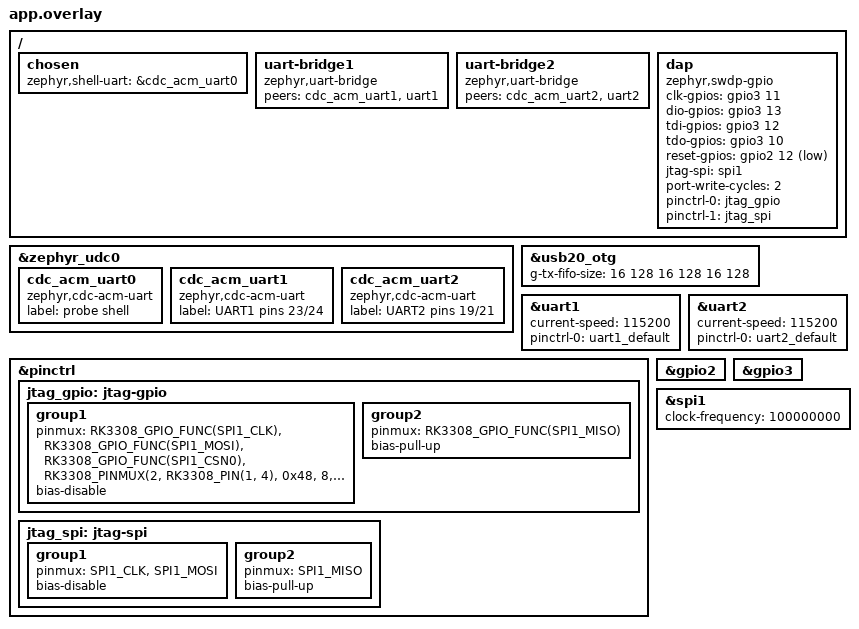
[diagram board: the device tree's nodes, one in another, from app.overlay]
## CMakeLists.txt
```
# SPDX-FileCopyrightText: Copyright The Zephyr Project Contributors
# SPDX-License-Identifier: Apache-2.0

cmake_minimum_required(VERSION 3.20.0)
find_package(Zephyr REQUIRED HINTS $ENV{ZEPHYR_BASE})
project(rk3308_usb_probe)

include(${ZEPHYR_BASE}/samples/subsys/usb/common/common.cmake)
target_sources(app PRIVATE src/main.c src/cpufreq.c)

target_sources_ifdef(CONFIG_DAP_BACKEND_TCP app PRIVATE src/dap.c)

if(CONFIG_SSH_SERVER)
  target_sources(app PRIVATE src/ssh.c)
  if(NOT CONFIG_USB_PROBE_SSH_HOST_KEY STREQUAL "")
    get_filename_component(host_key ${CONFIG_USB_PROBE_SSH_HOST_KEY}
                           ABSOLUTE BASE_DIR ${APPLICATION_SOURCE_DIR})
    set(gen_dir ${ZEPHYR_BINARY_DIR}/include/generated)
    generate_inc_file_for_target(app ${host_key} ${gen_dir}/ssh_host_key.der.inc)
    target_compile_definitions(app PRIVATE USB_PROBE_SSH_HOST_KEY_INC)
  endif()
endif()
```

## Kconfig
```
# Copyright The Zephyr Project Contributors
# SPDX-License-Identifier: Apache-2.0

# USB sample options (VID/PID, strings) of the in-tree USB samples
source "samples/subsys/usb/common/Kconfig.sample_usbd"

if SSH_SERVER

config USB_PROBE_SSH_USERNAME
	string "SSH user name (empty: any)"
	default "root"

config USB_PROBE_SSH_PASSWORD
	string "SSH password"
	default ""
	help
	  Stored in clear text in the image. Empty: the server is not
	  started.

config USB_PROBE_SSH_HOST_KEY
	string "RSA host key file (DER)"
	default ""
	help
	  Private RSA key built into the image, relative to the application
	  directory or absolute, e.g. made with
	  "openssl genpkey -algorithm RSA -pkeyopt rsa_keygen_bits:2048
	  -outform DER -out host_key.der". The probe has no storage, so
	  without it a new key (and fingerprint) is generated on every
	  boot.

config USB_PROBE_SSH_HOST_KEY_BITS
	int "Size of a host key generated at boot"
	default 2048

endif

source "Kconfig.zephyr"
```

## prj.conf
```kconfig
CONFIG_USB_DEVICE_STACK_NEXT=y
CONFIG_SAMPLE_USBD_PID=0x0001
CONFIG_SAMPLE_USBD_PRODUCT="RK3308 lab probe"
CONFIG_SAMPLE_USBD_MAX_POWER=250

CONFIG_SERIAL=y
CONFIG_UART_INTERRUPT_DRIVEN=y
CONFIG_UART_LINE_CTRL=y
CONFIG_UART_USE_RUNTIME_CONFIGURE=y
CONFIG_CDC_ACM_SERIAL_INITIALIZE_AT_BOOT=n
CONFIG_UART_BRIDGE_BUF_SIZE=4096

# probe shell on the first CDC ACM port, log on the console UART
CONFIG_SHELL=y
CONFIG_SHELL_BACKEND_SERIAL=y
CONFIG_SHELL_BACKEND_SERIAL_CHECK_DTR=y
CONFIG_SHELL_LOG_BACKEND=n
CONFIG_KERNEL_SHELL=y
CONFIG_DEVMEM_SHELL=y
# log off for now: with it on, nothing reaches UART0 on this board
CONFIG_LOG=n

# "kernel reboot": PSCI SYSTEM_RESET
CONFIG_REBOOT=y

# micro SD: FAT partition mounted at /SD:, the boot area (MBR, idbloader at
# sector 64, FIT at sector 16384) written by "fwupdate ymodem"
CONFIG_SDHC=y
CONFIG_DISK_ACCESS=y
CONFIG_SDMMC_STACK=y
CONFIG_DISK_DRIVER_SDMMC=y
CONFIG_FILE_SYSTEM=y
CONFIG_FILE_SYSTEM_SHELL=y
CONFIG_FAT_FILESYSTEM_ELM=y
CONFIG_FS_FATFS_LFN=y
# mkfs over the whole card would cover the boot area
CONFIG_FS_FATFS_MOUNT_MKFS=n
CONFIG_FWUPDATE=y
CONFIG_FWUPDATE_BOOT_DISK=y
CONFIG_FWUPDATE_BOOT_DISK_NAME="SD"
# up to the end of a FIT of at most 1 MiB at sector 16384
CONFIG_FWUPDATE_BOOT_DISK_SIZE=0x900000
CONFIG_MAIN_STACK_SIZE=4096

# "cpu freq": core clock with vdd_core (PWM regulator)
CONFIG_PWM=y
CONFIG_REGULATOR=y
```

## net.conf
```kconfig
# Ethernet (RMII + RTL8201F): DHCP, mDNS (rk3308-probe-<mac>.local), the
# shell over SSH. EXTRA_CONF_FILE=net.conf and
# -DCONFIG_USB_PROBE_SSH_PASSWORD=\"...\"; ssh root@rk3308-probe-<mac>.local
CONFIG_NETWORKING=y
CONFIG_NET_L2_ETHERNET=y
CONFIG_NET_IPV4=y
CONFIG_NET_IPV6=n
CONFIG_NET_TCP=y
CONFIG_NET_UDP=y
CONFIG_NET_DHCPV4=y
# first DISCOVER 1..2 s after the link, not up to 10 s (RFC 2131 4.4.1)
CONFIG_NET_DHCPV4_INITIAL_DELAY_MAX=2
CONFIG_NET_SOCKETS=y
CONFIG_NET_HOSTNAME_ENABLE=y
CONFIG_NET_HOSTNAME="rk3308-probe"
CONFIG_NET_HOSTNAME_UNIQUE=y
CONFIG_MDNS_RESPONDER=y
CONFIG_NET_SHELL=y
CONFIG_NET_PKT_RX_COUNT=32
CONFIG_NET_PKT_TX_COUNT=32
CONFIG_NET_BUF_RX_COUNT=64
CONFIG_NET_BUF_TX_COUNT=64
CONFIG_NET_RX_STACK_SIZE=4096
# no TRNG driver for the RK3308 yet: not a source of real entropy
CONFIG_TEST_RANDOM_GENERATOR=y
CONFIG_HWINFO_SHELL=y

CONFIG_SSH_SERVER=y
CONFIG_SSH_SERVER_MAX_CLIENTS=2
CONFIG_SSH_MAX_CHANNELS=2
CONFIG_SSH_MAX_HOST_KEYS=1
# the channel receive window: with the default 256 bytes, one round trip per
# 128 bytes caps an upload at about 20 kB/s
CONFIG_SSH_CHANNEL_BUF_SIZE=16384
CONFIG_MBEDTLS=y
# RSA key generation in main()
CONFIG_MAIN_STACK_SIZE=16384
# "fwupdate tcp" (nc -N <probe> 6969 < <img>-boot.bin) and
# "scp -O <img>-boot.bin root@<probe>:/fw"
CONFIG_FWUPDATE_TCP=y
CONFIG_SHELL_SSH_SCP=y
# ssh <probe> '<command>'
CONFIG_SHELL_SSH_EXEC=y
CONFIG_SHELL_DUMMY_INIT_LOG_LEVEL_NONE=y
CONFIG_SHELL_PROMPT_DUMMY=""
CONFIG_ZVFS_POLL_MAX=10
CONFIG_ZVFS_OPEN_MAX=16

# CMSIS-DAP over TCP (port 4441): SWD/JTAG on header 2, JTAG bytes by SPI1
CONFIG_GPIO=y
CONFIG_SPI=y
CONFIG_DAP=y
CONFIG_DAP_BACKEND_TCP=y
CONFIG_CMSIS_DAP_PROBE_NAME="RK3308 lab probe"
```

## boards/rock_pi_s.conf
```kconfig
# Buffer DMA (the FIFO mode does not complete control OUT data stages here).
# Hibernation off: power-down mode not verified on the RK3308.
CONFIG_UDC_DWC2_DMA=y
CONFIG_UDC_DWC2_HIBERNATION=n
# 512 bytes of driver thread stack are 96 % used on aarch64
CONFIG_UDC_DWC2_STACK_SIZE=1024
```

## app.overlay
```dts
/*
 * Copyright The Zephyr Project Contributors
 * SPDX-License-Identifier: Apache-2.0
 *
 * ACM0: probe shell. ACM1: UART1 (header pins 24 TX, 23 RX). ACM2: UART2
 * M0 (pins 19 TX, 21 RX). The host sets the line coding of each bridged
 * port. UART0 (pins 8/10) stays the console of the probe.
 */

/ {
	chosen {
		zephyr,shell-uart = &cdc_acm_uart0;
	};

	uart-bridge1 {
		compatible = "zephyr,uart-bridge";
		peers = <&cdc_acm_uart1 &uart1>;
	};

	uart-bridge2 {
		compatible = "zephyr,uart-bridge";
		peers = <&cdc_acm_uart2 &uart2>;
	};
};

&zephyr_udc0 {
	cdc_acm_uart0: cdc_acm_uart0 {
		compatible = "zephyr,cdc-acm-uart";
		label = "probe shell";
	};

	cdc_acm_uart1: cdc_acm_uart1 {
		compatible = "zephyr,cdc-acm-uart";
		label = "UART1 pins 23/24";
	};

	cdc_acm_uart2: cdc_acm_uart2 {
		compatible = "zephyr,cdc-acm-uart";
		label = "UART2 pins 19/21";
	};
};

/*
 * TX FIFO per IN endpoint, in the order the CDC ACM functions take them
 * (lowest free number first): notification (interrupt), data (bulk) for
 * each port. Bulk IN at high speed needs 128 words (512 bytes).
 */
&usb20_otg {
	g-tx-fifo-size = <16 128 16 128 16 128>;
};

&uart1 {
	status = "okay";
	current-speed = <115200>;
	pinctrl-0 = <&uart1_default>;
	pinctrl-names = "default";
};

&uart2 {
	status = "okay";
	current-speed = <115200>;
	pinctrl-0 = <&uart2_default>;
	pinctrl-names = "default";
};

/*
 * JTAG/SWD on header 2: 41 TCK/SWCLK (GPIO3_B3, SPI1_CLK), 39 TMS/SWDIO
 * (GPIO3_B5), 40 TDI (GPIO3_B4, SPI1_MOSI), 42 TDO (GPIO3_B2, SPI1_MISO),
 * 43 nRESET (GPIO2_B4). GPIO functions by default; SPI1 shifts the whole
 * bytes of JTAG sequences with its pads switched to SPI ("spi" state).
 * Served as CMSIS-DAP over TCP (net.conf).
 */
&pinctrl {
	jtag_gpio: jtag-gpio {
		group1 {
			pinmux = <RK3308_GPIO_FUNC(SPI1_CLK)>, <RK3308_GPIO_FUNC(SPI1_MOSI)>,
				 <RK3308_GPIO_FUNC(SPI1_CSN0)>,
				 <RK3308_PINMUX(2, RK3308_PIN(1, 4), 0x48, 8, 2, 0)>;
			bias-disable;
		};

		group2 {
			pinmux = <RK3308_GPIO_FUNC(SPI1_MISO)>;
			bias-pull-up;
		};
	};

	jtag_spi: jtag-spi {
		group1 {
			pinmux = <SPI1_CLK>, <SPI1_MOSI>;
			bias-disable;
		};

		group2 {
			pinmux = <SPI1_MISO>;
			bias-pull-up;
		};
	};
};

&gpio2 {
	status = "okay";
};

&gpio3 {
	status = "okay";
};

/* SCK up to 50 MHz (spiclk / 2) */
&spi1 {
	clock-frequency = <100000000>;
	status = "okay";
};

/ {
	dap: dap {
		compatible = "zephyr,swdp-gpio";
		clk-gpios = <&gpio3 11 GPIO_ACTIVE_HIGH>;
		dio-gpios = <&gpio3 13 GPIO_ACTIVE_HIGH>;
		tdi-gpios = <&gpio3 12 GPIO_ACTIVE_HIGH>;
		tdo-gpios = <&gpio3 10 GPIO_ACTIVE_HIGH>;
		reset-gpios = <&gpio2 12 GPIO_ACTIVE_LOW>;
		jtag-spi = <&spi1>;
		port-write-cycles = <2>;
		pinctrl-0 = <&jtag_gpio>;
		pinctrl-1 = <&jtag_spi>;
		pinctrl-names = "default", "spi";
	};
};
```

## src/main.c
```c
/*
 * Copyright The Zephyr Project Contributors
 * SPDX-License-Identifier: Apache-2.0
 *
 * RK3308 as a lab probe: USB composite device with CDC ACM ports, the first
 * one the probe's shell, the others bridged to UARTs (zephyr,uart-bridge);
 * the line coding the host sets on a bridged port is applied to its UART.
 * The FAT partition of a micro SD card is mounted at /SD:; "fwupdate"
 * writes the card's boot area. With net.conf: Ethernet with DHCP, mDNS
 * (rk3308-probe-<mac>.local), the shell over SSH and CMSIS-DAP over TCP
 * (SWD/JTAG on header 2).
 */

#include <ff.h>
#include <sample_usbd.h>

#include <zephyr/device.h>
#include <zephyr/drivers/uart/uart_bridge.h>
#include <zephyr/fs/fs.h>
#include <zephyr/kernel.h>
#include <zephyr/logging/log.h>
#include <zephyr/net/net_if.h>
#include <zephyr/net/dhcpv4.h>
#include <zephyr/sys/printk.h>
#include <zephyr/usb/usbd.h>

#include "probe.h"

LOG_MODULE_REGISTER(usb_probe, LOG_LEVEL_INF);

static const struct device *const bridges[] = {
	DT_FOREACH_STATUS_OKAY(zephyr_uart_bridge, DEVICE_DT_GET_COMMA)
};

static FATFS sd_fat;
static struct fs_mount_t sd_mnt = {
	.type = FS_FATFS,
	.fs_data = &sd_fat,
	.mnt_point = "/SD:",
};

static void msg_cb(struct usbd_context *const ctx, const struct usbd_msg *msg)
{
	if (msg->type == USBD_MSG_CDC_ACM_LINE_CODING ||
	    msg->type == USBD_MSG_CDC_ACM_CONTROL_LINE_STATE) {
		/* bridges not holding msg->dev skip it */
		for (size_t i = 0; i < ARRAY_SIZE(bridges); i++) {
			uart_bridge_settings_update(msg->dev, bridges[i]);
		}
		return;
	}
	LOG_INF("USB: %s", usbd_msg_type_string(msg->type));

	if (usbd_can_detect_vbus(ctx)) {
		if (msg->type == USBD_MSG_VBUS_READY && usbd_enable(ctx) != 0) {
			LOG_ERR("USB enable failed");
		}
		if (msg->type == USBD_MSG_VBUS_REMOVED && usbd_disable(ctx) != 0) {
			LOG_ERR("USB disable failed");
		}
	}
}

int main(void)
{
	int ret;
	struct usbd_context *usbd = sample_usbd_init_device(msg_cb);

	if (usbd == NULL) {
		LOG_ERR("USB device init failed");
		return -ENODEV;
	}
	if (!usbd_can_detect_vbus(usbd) && usbd_enable(usbd) != 0) {
		LOG_ERR("USB enable failed");
		return -EIO;
	}
	LOG_INF("USB probe: %zu UART bridges", ARRAY_SIZE(bridges));

	ret = fs_mount(&sd_mnt);
	printk("SD: %s (%d)\n", ret == 0 ? "mounted at /SD:" : "no card or no FAT", ret);

	if (IS_ENABLED(CONFIG_NET_DHCPV4) && net_if_get_default() != NULL) {
		struct net_linkaddr *ll = net_if_get_link_addr(net_if_get_default());

		printk("net: MAC %02x:%02x:%02x:%02x:%02x:%02x, DHCP\n", ll->addr[0],
		       ll->addr[1], ll->addr[2], ll->addr[3], ll->addr[4], ll->addr[5]);
		net_dhcpv4_start(net_if_get_default());
	}
	if (IS_ENABLED(CONFIG_SSH_SERVER)) {
		probe_ssh_start();
	}
	if (IS_ENABLED(CONFIG_DAP_BACKEND_TCP)) {
		probe_dap_start();
	}
	return 0;
}
```

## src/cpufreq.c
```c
/*
 * Copyright The Zephyr Project Contributors
 * SPDX-License-Identifier: Apache-2.0
 *
 * "cpu freq [MHz]": core clock at one of the operating points of the Linux
 * RK3308 devicetree, vdd_core (PWM regulator) set to the voltage of the
 * point first when the clock goes up and after it when it goes down.
 * "cpu vdd <mV>" sets vdd_core alone (to check it with a meter).
 * Until either is used, vdd_core runs at the voltage strapped on the board.
 */

#include <stdlib.h>

#include <zephyr/device.h>
#include <zephyr/drivers/clock_control.h>
#include <zephyr/drivers/regulator.h>
#include <zephyr/dt-bindings/clock/rk3308-cru.h>
#include <zephyr/shell/shell.h>

struct opp {
	uint16_t mhz;
	uint16_t mv;
};

static const struct opp opps[] = {
	{408, 950},
	{600, 950},
	{816, 1025},
	{1008, 1125},
};

static const struct device *const cru = DEVICE_DT_GET(DT_NODELABEL(cru_clk));
static const struct device *const vdd = DEVICE_DT_GET(DT_NODELABEL(vdd_core));

static void show(const struct shell *sh)
{
	uint32_t hz = 0;
	int32_t uv;

	(void)clock_control_get_rate(cru, (clock_control_subsys_t)ARMCLK, &hz);
	if (regulator_get_voltage(vdd, &uv) == 0) {
		shell_print(sh, "cores %u MHz, vdd_core %d mV", hz / 1000000U, uv / 1000);
	} else {
		shell_print(sh, "cores %u MHz, vdd_core as strapped (not set)", hz / 1000000U);
	}
}

static int set_mv(const struct shell *sh, uint32_t mv)
{
	int ret = regulator_set_voltage(vdd, mv * 1000, mv * 1000);

	if (ret != 0) {
		shell_error(sh, "vdd_core %u mV: %d", mv, ret);
	}
	return ret;
}

static int cmd_freq(const struct shell *sh, size_t argc, char **argv)
{
	const struct opp *o = NULL;
	uint32_t old = 0, mhz;
	int ret;

	if (argc < 2) {
		show(sh);
		return 0;
	}
	mhz = strtoul(argv[1], NULL, 0);
	for (size_t i = 0; i < ARRAY_SIZE(opps); i++) {
		if (opps[i].mhz == mhz) {
			o = &opps[i];
		}
	}
	if (o == NULL) {
		shell_error(sh, "operating points: 408 600 816 1008 MHz");
		return -EINVAL;
	}
	(void)clock_control_get_rate(cru, (clock_control_subsys_t)ARMCLK, &old);
	if (mhz * 1000000U >= old) {
		ret = set_mv(sh, o->mv);
		if (ret != 0) {
			return ret;
		}
	}
	ret = clock_control_set_rate(cru, (clock_control_subsys_t)ARMCLK,
				     (clock_control_subsys_rate_t)(uintptr_t)(mhz * 1000000U));
	if (ret != 0) {
		shell_error(sh, "core clock %u MHz: %d", mhz, ret);
		return ret;
	}
	if (mhz * 1000000U < old) {
		ret = set_mv(sh, o->mv);
		if (ret != 0) {
			return ret;
		}
	}
	show(sh);
	return 0;
}

static int cmd_vdd(const struct shell *sh, size_t argc, char **argv)
{
	ARG_UNUSED(argc);

	if (set_mv(sh, strtoul(argv[1], NULL, 0)) != 0) {
		return -EINVAL;
	}
	show(sh);
	return 0;
}

SHELL_STATIC_SUBCMD_SET_CREATE(sub_cpu,
	SHELL_CMD_ARG(freq, NULL, "[408|600|816|1008]: core clock and vdd_core", cmd_freq, 1, 1),
	SHELL_CMD_ARG(vdd, NULL, "<mV>: vdd_core alone (827..1340)", cmd_vdd, 2, 0),
	SHELL_SUBCMD_SET_END);
SHELL_CMD_REGISTER(cpu, &sub_cpu, "Core clock and supply", NULL);
```

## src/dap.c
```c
/*
 * Copyright The Zephyr Project Contributors
 * SPDX-License-Identifier: Apache-2.0
 *
 * CMSIS-DAP (SWD and JTAG on header 2) over TCP, for OpenOCD:
 *   adapter driver cmsis-dap
 *   cmsis-dap backend tcp
 *   cmsis-dap tcp host <probe>
 *
 * "dap loopback [kHz]" checks the JTAG path with TDI wired to TDO (header
 * pins 40 and 42): sequences of every length from 1 to 200 bits, then
 * 64 KiB through SPI for the throughput. Not while a client is connected.
 */

#include <stdlib.h>
#include <string.h>

#include <zephyr/dap/dap_link.h>
#include <zephyr/device.h>
#include <zephyr/drivers/swdp.h>
#include <zephyr/kernel.h>
#include <zephyr/random/random.h>
#include <zephyr/shell/shell.h>
#include <zephyr/sys/printk.h>

#include "probe.h"

DAP_LINK_CONTEXT_DEFINE(dap_ctx, DEVICE_DT_GET(DT_NODELABEL(dap)));

void probe_dap_start(void)
{
	int ret = dap_link_init(&dap_ctx);

	if (ret == 0) {
		ret = dap_link_backend_tcp_init(&dap_ctx);
	}
	if (ret != 0) {
		printk("dap: %d\n", ret);
		return;
	}
	printk("dap: CMSIS-DAP on TCP port %d\n", CONFIG_DAP_BACKEND_TCP_PORT);
}

static uint8_t lb_tdi[1024];
static uint8_t lb_tdo[1024];

static int lb_check(const struct shell *sh, const struct device *dev, uint32_t bits)
{
	size_t n = (bits + 7U) / 8U;
	int ret;

	sys_rand_get(lb_tdi, n);
	memset(lb_tdo, 0x5a, n);
	ret = swdp_jtag_sequence(dev, bits, false, lb_tdi, lb_tdo);
	if (ret != 0) {
		shell_error(sh, "%u bits: %d", bits, ret);
		return ret;
	}
	if (bits % 8U != 0U) {
		uint8_t mask = BIT(bits % 8U) - 1U;

		lb_tdi[n - 1U] &= mask;
		lb_tdo[n - 1U] &= mask;
	}
	if (memcmp(lb_tdi, lb_tdo, n) != 0) {
		for (size_t i = 0; i < n; i++) {
			if (lb_tdi[i] != lb_tdo[i]) {
				shell_error(sh, "%u bits: byte %zu sent %02x, read %02x", bits, i,
					    lb_tdi[i], lb_tdo[i]);
				break;
			}
		}
		return -EIO;
	}
	return 0;
}

static int cmd_loopback(const struct shell *sh, size_t argc, char **argv)
{
	const struct device *dev = dap_ctx.dev;
	uint32_t khz = argc > 1 ? strtoul(argv[1], NULL, 0) : 10000U;
	int64_t t0, ms;
	int ret;

	ret = swdp_port_on(dev);
	if (ret == 0) {
		ret = swdp_set_clock(dev, khz * 1000U);
	}
	if (ret != 0) {
		shell_error(sh, "port: %d", ret);
		return ret;
	}
	for (uint32_t bits = 1U; bits <= 200U && ret == 0; bits++) {
		ret = lb_check(sh, dev, bits);
	}
	if (ret == 0) {
		shell_print(sh, "1..200 bits at %u kHz: OK", khz);
		t0 = k_uptime_get();
		for (int i = 0; i < 64 && ret == 0; i++) {
			ret = lb_check(sh, dev, sizeof(lb_tdi) * 8U);
		}
		ms = k_uptime_get() - t0;
		if (ret == 0) {
			shell_print(sh, "64 KiB in %lld ms (%lld kbit/s)", ms,
				    ms > 0 ? (64LL * 8192LL) / ms : 0LL);
		}
	}
	(void)swdp_port_off(dev);
	return ret;
}

SHELL_STATIC_SUBCMD_SET_CREATE(sub_dap,
	SHELL_CMD_ARG(loopback, NULL, "[kHz]: JTAG check, TDI (pin 40) wired to TDO (pin 42)",
		      cmd_loopback, 1, 1),
	SHELL_SUBCMD_SET_END);
SHELL_CMD_REGISTER(dap, &sub_dap, "CMSIS-DAP probe", NULL);
```

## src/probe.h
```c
/*
 * Copyright The Zephyr Project Contributors
 * SPDX-License-Identifier: Apache-2.0
 */

#ifndef USB_PROBE_PROBE_H_
#define USB_PROBE_PROBE_H_

/* SSH server with the shell backend (src/ssh.c, with net.conf) */
void probe_ssh_start(void);

/* CMSIS-DAP over TCP (src/dap.c, with net.conf) */
void probe_dap_start(void);

#endif /* USB_PROBE_PROBE_H_ */
```

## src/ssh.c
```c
/*
 * Copyright The Zephyr Project Contributors
 * SPDX-License-Identifier: Apache-2.0
 *
 * SSH server with the shell backend, on all addresses: the host key built
 * into the image (USB_PROBE_SSH_HOST_KEY) or a new one per boot.
 */

#include <stdint.h>
#include <string.h>

#include <zephyr/kernel.h>
#include <zephyr/net/net_ip.h>
#include <zephyr/net/ssh/keygen.h>
#include <zephyr/net/ssh/server.h>
#include <zephyr/shell/shell_ssh.h>
#include <zephyr/sys/printk.h>

#include "probe.h"

#define HOST_KEY 0

#if defined(USB_PROBE_SSH_HOST_KEY_INC)
static const uint8_t host_key_der[] = {
#include "ssh_host_key.der.inc"
};
#endif

static int host_key_setup(void)
{
	int ret;

#if defined(USB_PROBE_SSH_HOST_KEY_INC)
	ret = ssh_keygen_import(HOST_KEY, true, SSH_HOST_KEY_FORMAT_DER, host_key_der,
				sizeof(host_key_der));
	if (ret != 0) {
		printk("ssh: host key import: %d\n", ret);
	}
#else
	int64_t t0;

	printk("ssh: generating a %d bit RSA host key\n", CONFIG_USB_PROBE_SSH_HOST_KEY_BITS);
	t0 = k_uptime_get();
	ret = ssh_keygen(HOST_KEY, SSH_HOST_KEY_TYPE_RSA, CONFIG_USB_PROBE_SSH_HOST_KEY_BITS);
	if (ret != 0) {
		printk("ssh: host key generation: %d\n", ret);
	} else {
		printk("ssh: host key ready after %lld ms\n", k_uptime_get() - t0);
	}
#endif
	return ret;
}

void probe_ssh_start(void)
{
	struct net_sockaddr_in addr = {
		.sin_family = NET_AF_INET,
		.sin_port = net_htons(CONFIG_SSH_PORT),
	};
	const char *user = CONFIG_USB_PROBE_SSH_USERNAME;
	int ret;

	if (CONFIG_USB_PROBE_SSH_PASSWORD[0] == '\0') {
		printk("ssh: no password configured, server not started\n");
		return;
	}
	if (host_key_setup() != 0) {
		return;
	}
	ssh_server_set_banner_text("RK3308 lab probe (" CONFIG_BOARD_TARGET ")");
	ret = ssh_server_start(ssh_server_instance(0), (struct net_sockaddr *)&addr, HOST_KEY,
			       user[0] != '\0' ? user : NULL, CONFIG_USB_PROBE_SSH_PASSWORD, NULL,
			       0, shell_sshd_event_callback, shell_sshd_transport_event_callback,
			       NULL);
	if (ret != 0) {
		printk("ssh: server start: %d\n", ret);
		return;
	}
	printk("ssh: listening on port %d\n", CONFIG_SSH_PORT);
}
```
